# R7KA8P1AD register map
Vendor: Renesas Electronics Corporation; Series: RA8; File version: 1.10.02
CPU: CM85 r0p2, little endian, MPU, FPU, VTOR, 4 interrupt priority bits, 96 interrupts
Registers are 32-bit, read-write, reset 0x0 unless marked. A register's access mark holds for its fields unless they carry their own. Offsets are from the block's base; [hi:lo] are bit positions; {n}, {i} and the like mark numbered series; 'fields as' and 'values as' point back to an identical list.

## RMPU — Renesas Memory Protection Unit
Base 0x40000000
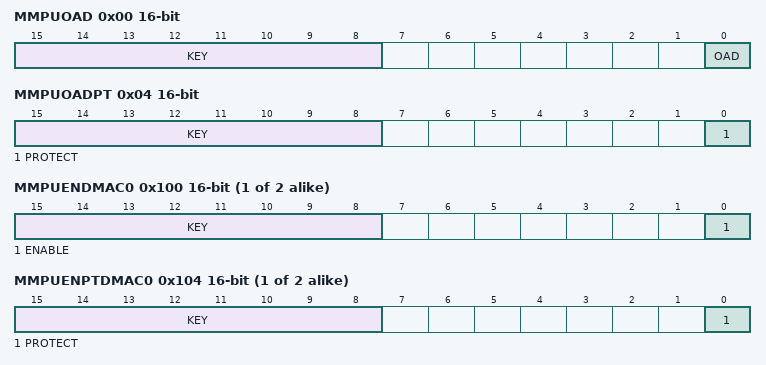
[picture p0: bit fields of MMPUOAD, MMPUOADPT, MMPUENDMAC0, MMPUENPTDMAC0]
0x00 MMPUOAD 16-bit — MMPU Operation After Detection Register
  [15:8] KEY — Key Code
  [0] OAD — Operation after detection
    0=IRQ; 1=Reset
0x04 MMPUOADPT 16-bit — MMPU Operation After Detection Protect Register
  [15:8] KEY wo — Key Code
  [0] PROTECT — Protection of register
    0=MMPUOAD register writing is possible; 1=MMPUOAD register writing is protected. Read is possible.
{0x100+0x200*i} MMPUENDMAC{i} (i=0..1) 16-bit — MMPU Enable Register for DMAC
  [15:8] KEY wo — Key Code
  [0] ENABLE — Bus master MPU of DMAC Enable
    0=Bus master MPU of DMAC is disabled; 1=Bus master MPU of DMAC is enabled
{0x104+0x200*i} MMPUENPTDMAC{i} (i=0..1) 16-bit — MMPU Enable Protect Register for DMAC {i}
  [15:8] KEY wo — Key Code
  [0] PROTECT — Protection of register
    0=MMPUENDMACm register write is possible; 1=MMPUENDMACm register write is protected. Read is possible.
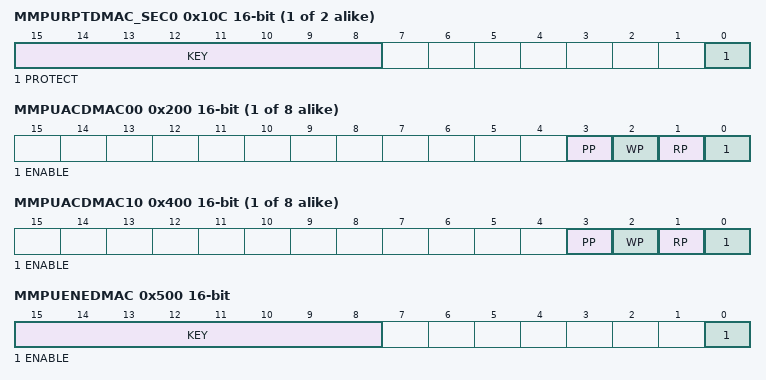
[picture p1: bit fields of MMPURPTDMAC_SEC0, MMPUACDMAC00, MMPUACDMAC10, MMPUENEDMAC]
{0x10C+0x200*i} MMPURPTDMAC_SEC{i} (i=0..1) 16-bit — MMPU Regions Protect Register for DMAC Secure {i}
  [15:8] KEY wo — Key Code
  [0] PROTECT — Protection of register
    0=Bus master MPU register for DMAC Secure write is possible; 1=Bus master MPU register for DMAC Secure write is protected. Read is possible.
{0x200+0x10*i} MMPUACDMAC0{i} (i=0..7) 16-bit — MMPU Access Control Register for DMAC
  [3] PP — Privilege protection
    0=Unprivileged access permission; 1=Unprivileged access protection
  [2] WP — Write protection
    0=Write permission; 1=Write protection
  [1] RP — Read protection
    0=Read permission; 1=Read protection
  [0] ENABLE — Region Enable
    0=DMAC region n unit is disabled; 1=DMAC region n unit is enabled
{0x204+0x10*i} MMPUSDMAC0{i} (i=0..7) (reset mask 0x1F) — MMPU Start Address Register for DMAC (n = 00 to 07)
{0x208+0x10*i} MMPUEDMAC0{i} (i=0..7) reset 0x1F (reset mask 0x1F) — MMPU End Address Register for DMAC (n = 00 to 07)
{0x400+0x10*i} MMPUACDMAC1{i} (i=0..7) 16-bit — MMPU Access Control Register for DMAC
  fields as MMPUACDMAC00
{0x404+0x10*i} MMPUSDMAC1{i} (i=0..7) (reset mask 0x1F) — MMPU Start Address Register for DMAC (n = 00 to 07)
{0x408+0x10*i} MMPUEDMAC1{i} (i=0..7) reset 0x1F (reset mask 0x1F) — MMPU End Address Register for DMAC (n = 00 to 07)
0x500 MMPUENEDMAC 16-bit — MMPU Enable Register for EDMAC
  [15:8] KEY wo — Key Code
  [0] ENABLE — Bus master MPU of EDMAC Enable
    0=Bus master MPU of EDMAC is disabled; 1=Bus master MPU of EDMAC is enabled
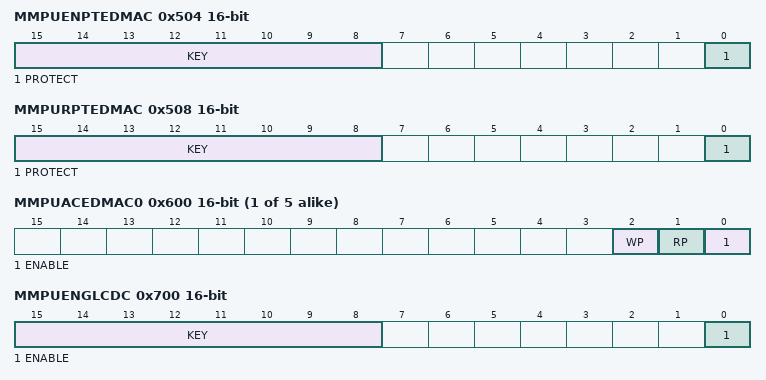
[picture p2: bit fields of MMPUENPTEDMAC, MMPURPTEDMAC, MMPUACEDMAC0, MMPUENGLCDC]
0x504 MMPUENPTEDMAC 16-bit — MMPU Enable Protect Register for EDMAC
  [15:8] KEY wo — Key Code
  [0] PROTECT — Protection of register
    0=MMPUENEDMAC register write is possible; 1=MMPUENEDMAC register write is protected. Read is possible.
0x508 MMPURPTEDMAC 16-bit — MMPU Regions Protect Register for EDMAC
  [15:8] KEY wo — Key Code
  [0] PROTECT — Protection of register
    0=Bus master MPU register for EDMAC write is possible; 1=Bus master MPU register for EDMAC write is protected. Read is possible.
{0x600+0x10*i} MMPUACEDMAC{i} (i=0..4) 16-bit — MMPU Access Control Register for EDMAC
  [2] WP — Write protection
    0=Write permission; 1=Write protection
  [1] RP — Read protection
    0=Read permission; 1=Read protection
  [0] ENABLE — Region Enable
    0=EDMAC region n unit is disabled; 1=EDMAC region n unit is enabled
{0x604+0x10*i} MMPUSEDMAC{i} (i=0..4) (reset mask 0x1F) — MMPU Start Address Register for EDMAC (n = 0 to 4)
{0x608+0x10*i} MMPUEEDMAC{i} (i=0..4) reset 0x1F (reset mask 0x1F) — MMPU End Address Register for EDMAC
0x700 MMPUENGLCDC 16-bit — MMPU Enable Register for GLCDC
  [15:8] KEY wo — Key Code
  [0] ENABLE — Bus master MPU of GLCDC Enable
    0=Bus master MPU of GLCDC is disabled; 1=Bus master MPU of GLCDC is enabled
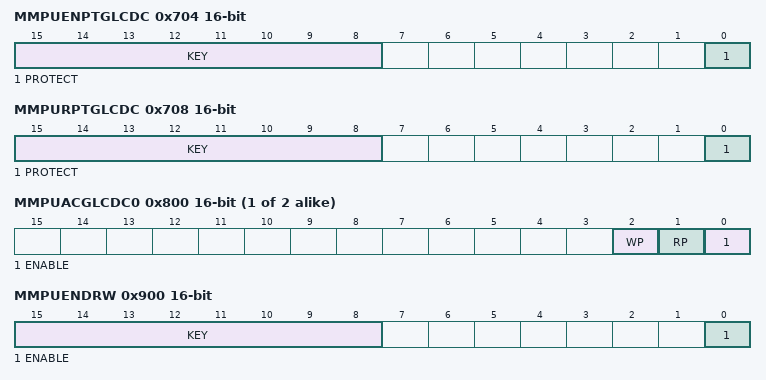
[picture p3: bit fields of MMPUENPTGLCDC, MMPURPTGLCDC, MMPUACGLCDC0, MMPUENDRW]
0x704 MMPUENPTGLCDC 16-bit — MMPU Enable Protect Register for GLCDC
  [15:8] KEY wo — Key Code
  [0] PROTECT — Protection of register
    0=MMPUENGLCDC register write is possible; 1=MMPUENGLCDC register write is protected. Read is possible.
0x708 MMPURPTGLCDC 16-bit — MMPU Regions Protect Register for GLCDC
  [15:8] KEY wo — Key Code
  [0] PROTECT — Protection of register
    0=Bus master MPU register for GLCDC write is possible; 1=Bus master MPU register for GLCDC write is protected. Read is possible.
{0x800+0x10*i} MMPUACGLCDC{i} (i=0..1) 16-bit — MMPU Access Control Register for GLCDC (n = 0, 1)
  [2] WP — Write protection
    0=Write permission; 1=Write protection
  [1] RP — Read protection
    0=Read permission; 1=Read protection
  [0] ENABLE — Region Enable
    0=GLCDC region n unit is disabled; 1=GLCDC region n unit is enabled
{0x804+0x10*i} MMPUSGLCDC{i} (i=0..1) (reset mask 0x3FF) — MMPU Start Address Register for GLCDC (n = 0, 1)
{0x808+0x10*i} MMPUEGLCDC{i} (i=0..1) reset 0x3FF (reset mask 0x3FF) — MMPU End Address Register for GLCDC (n = 0, 1)
0x900 MMPUENDRW 16-bit — MMPU Enable Register for DRW
  [15:8] KEY wo — Key Code
  [0] ENABLE — Bus master MPU of DRW Enable
    0=Bus master MPU of DRW is disabled; 1=Bus master MPU of DRW is enabled
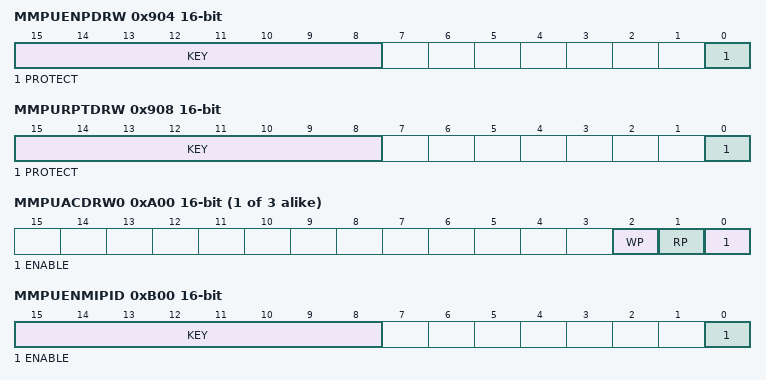
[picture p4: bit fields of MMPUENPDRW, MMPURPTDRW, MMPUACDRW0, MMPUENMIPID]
0x904 MMPUENPDRW 16-bit — MMPU Enable Protect Register for DRW
  [15:8] KEY wo — Key Code
  [0] PROTECT — Protection of register
    0=MMPUENDRW register write is possible; 1=MMPUENDRW register write is protected. Read is possible.
0x908 MMPURPTDRW 16-bit — MMPU Regions Protect Register for DRW
  [15:8] KEY wo — Key Code
  [0] PROTECT — Protection of register
    0=Bus master MPU register for DRW write is possible; 1=Bus master MPU register for DRW write is protected. Read is possible.
{0xA00+0x10*i} MMPUACDRW{i} (i=0..2) 16-bit — MMPU Access Control Register for DRW (n = 0 to 2)
  [2] WP — Write protection
    0=Write permission; 1=Write protection
  [1] RP — Read protection
    0=Read permission; 1=Read protection
  [0] ENABLE — Region Enable
    0=DRW region n unit is disabled; 1=DRW region n unit is enabled
{0xA04+0x10*i} MMPUSDRW{i} (i=0..2) (reset mask 0x3FF) — MMPU Start Address Register for DRW (n = 0 to 2)
{0xA08+0x10*i} MMPUEDRW{i} (i=0..2) reset 0x3FF (reset mask 0x3FF) — MMPU End Address Register for DRW (n = 0 to 2)
0xB00 MMPUENMIPID 16-bit — MMPU Enable Register for MIPI-DSI
  [15:8] KEY wo — Key Code
  [0] ENABLE — Bus master MPU of MIPI-DSI Enable
    0=Bus master MPU of MIPI-DSI is disabled; 1=Bus master MPU of MIPI-DSI is enabled
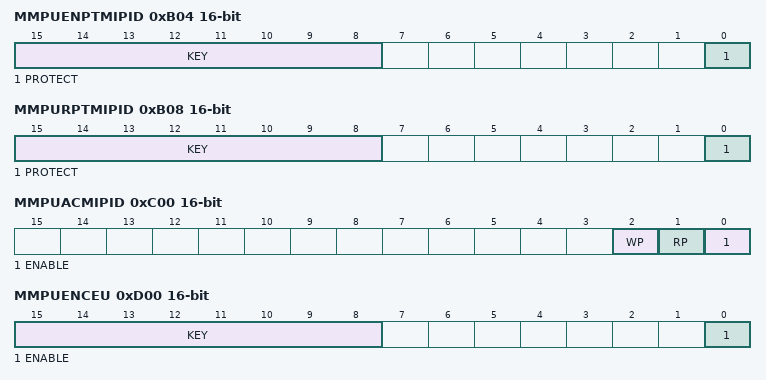
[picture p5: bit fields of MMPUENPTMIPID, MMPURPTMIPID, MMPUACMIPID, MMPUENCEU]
0xB04 MMPUENPTMIPID 16-bit — MMPU Enable Protect Register for MIPI-DSI
  [15:8] KEY wo — Key Code
  [0] PROTECT — Protection of register
    0=MMPUENMIPID register write is possible; 1=MMPUENMIPID register write is protected. Read is possible.
0xB08 MMPURPTMIPID 16-bit — MMPU Regions Protect Register for MIPI-DSI
  [15:8] KEY wo — Key Code
  [0] PROTECT — Protection of register
    0=Bus master MPU register for MIPI-DSI write is possible; 1=Bus master MPU register for MIPI-DSI write is protected. Read is possible.
0xC00 MMPUACMIPID 16-bit — MMPU Access Control Register for MIPI-DSI
  [2] WP — Write protection
    0=Write permission; 1=Write protection
  [1] RP — Read protection
    0=Read permission; 1=Read protection
  [0] ENABLE — Region Enable
    0=MIPI DSI region unit is disabled; 1=MIPI DSI region unit is enabled
0xC04 MMPUSMIPID (reset mask 0xFFF) — MMPU Start Address Register for MIPI-DSI
0xC08 MMPUEMIPID reset 0xFFF (reset mask 0xFFF) — MMPU End Address Register for MIPI-DSI
0xD00 MMPUENCEU 16-bit — MMPU Enable Register for CEU
  [15:8] KEY wo — Key Code
  [0] ENABLE — Bus master MPU of CEU Enable
    0=Bus master MPU of CEU is disabled; 1=Bus master MPU of CEU is enabled
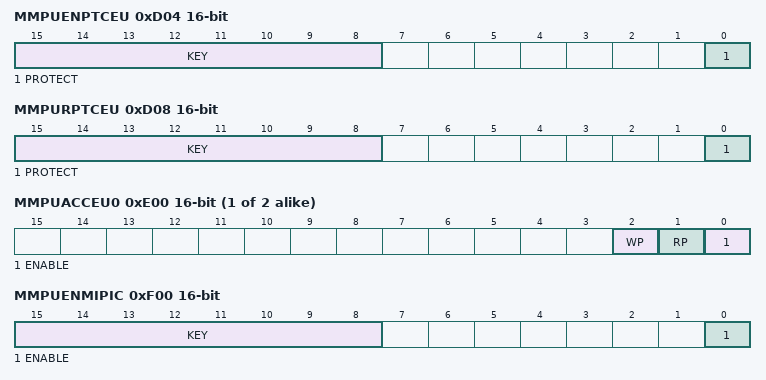
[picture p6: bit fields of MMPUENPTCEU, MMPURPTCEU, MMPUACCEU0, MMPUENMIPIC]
0xD04 MMPUENPTCEU 16-bit — MMPU Enable Protect Register for CEU
  [15:8] KEY wo — Key Code
  [0] PROTECT — Protection of register
    0=MMPUENCEU register write is possible; 1=MMPUENCEU register write is protected. Read is possible.
0xD08 MMPURPTCEU 16-bit — MMPU Regions Protect Register for CEU
  [15:8] KEY wo — Key Code
  [0] PROTECT — Protection of register
    0=Bus master MPU register for CEU write is possible; 1=Bus master MPU register for CEU write is protected. Read is possible.
{0xE00+0x10*i} MMPUACCEU{i} (i=0..1) 16-bit — MMPU Access Control Register for CEU (n = 0, 1)
  [2] WP — Write protection
    0=Write permission; 1=Write protection
  [1] RP — Read protection
    0=Read permission; 1=Read protection
  [0] ENABLE — Region Enable
    0=CEU region n unit is disabled; 1=CEU region n unit is enabled
{0xE04+0x10*i} MMPUSCEU{i} (i=0..1) (reset mask 0xFFF) — MMPU Start Address Register for CEU (n = 0, 1)
{0xE08+0x10*i} MMPUECEU{i} (i=0..1) reset 0xFFF (reset mask 0xFFF) — MMPU End Address Register for CEU (n = 0, 1)
0xF00 MMPUENMIPIC 16-bit — MMPU Enable Register for MIPI-CSI by VIN
  [15:8] KEY wo — Key Code
  [0] ENABLE — Bus master MPU of MIPI-CSI Enable
    0=Bus master MPU of MIPI-CSI is disabled; 1=Bus master MPU of MIPI-CSI is enabled
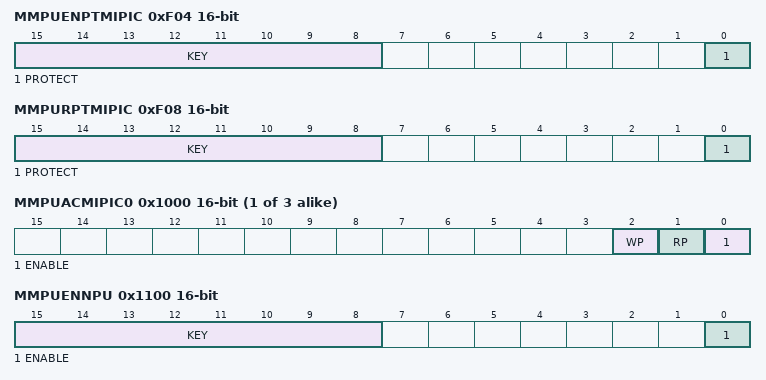
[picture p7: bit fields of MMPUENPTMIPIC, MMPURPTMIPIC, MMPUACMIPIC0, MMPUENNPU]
0xF04 MMPUENPTMIPIC 16-bit — MMPU Enable Protect Register for MIPI-CSI by VIN
  [15:8] KEY wo — Key Code
  [0] PROTECT — Protection of register
    0=MMPUENMIPIC register write is possible; 1=MMPUENMIPIC register write is protected. Read is possible.
0xF08 MMPURPTMIPIC 16-bit — MMPU Regions Protect Register for MIPI-CSI by VIN
  [15:8] KEY wo — Key Code
  [0] PROTECT — Protection of register
    0=Bus master MPU register for MIPI-CSI write is possible; 1=Bus master MPU register for MIPI-CSI write is protected. Read is possible.
{0x1000+0x10*i} MMPUACMIPIC{i} (i=0..2) 16-bit — MMPU Access Control Register for MIPI-CSI via VIN (n = 0 to 2)
  [2] WP — Write protection
    0=Write permission; 1=Write protection
  [1] RP — Read protection
    0=Read permission; 1=Read protection
  [0] ENABLE — Region Enable
    0=MIPI region n unit is disabled; 1=MIPI region n unit is enabled
{0x1004+0x10*i} MMPUSMIPIC{i} (i=0..2) (reset mask 0xFFF) — MMPU Start Address Register for MIPI-CSI via VIN (n = 0 to 2)
{0x1008+0x10*i} MMPUEMIPIC{i} (i=0..2) (reset mask 0xFFF) — MMPU End Address Register for MIPI-CSI via VIN (n = 0 to 2)
0x1100 MMPUENNPU 16-bit — MMPU Enable Register for NPU
  [15:8] KEY wo — Key Code
  [0] ENABLE — Bus master MPU of NPU Enable
    0=Bus master MPU of NPU is disabled; 1=Bus master MPU of NPU is enabled
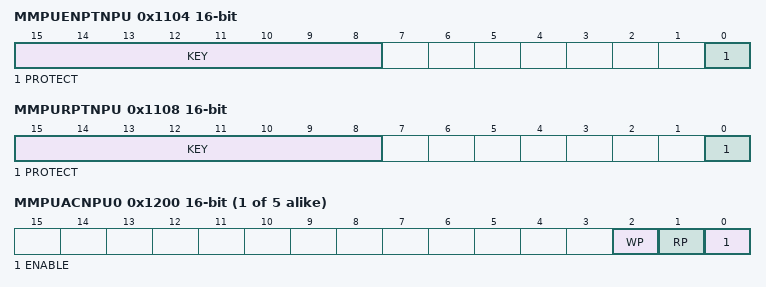
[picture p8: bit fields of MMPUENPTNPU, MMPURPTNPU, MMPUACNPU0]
0x1104 MMPUENPTNPU 16-bit — MMPU Enable Protect Register for NPU
  [15:8] KEY wo — Key Code
  [0] PROTECT — Protection of register
    0=MMPUENNPU register write is possible; 1=MMPUENNPU register write is protected. Read is possible.
0x1108 MMPURPTNPU 16-bit — MMPU Regions Protect Register for NPU
  [15:8] KEY wo — Key Code
  [0] PROTECT — Protection of register
    0=Bus master MPU register for NPU write is possible; 1=Bus master MPU register for NPU write is protected. Read is possible.
{0x1200+0x10*i} MMPUACNPU{i} (i=0..4) 16-bit — MMPU Access Control Register for NPU (n = 0 to 4)
  [2] WP — Write protection
    0=Write permission; 1=Write protection
  [1] RP — Read protection
    0=Read permission; 1=Read protection
  [0] ENABLE — Region Enable
    0=NPU region n unit is disabled; 1=NPU region n unit is enabled
{0x1204+0x10*i} MMPUSNPU{i} (i=0..4) (reset mask 0xFFF) — MMPU Start Address Register for NPU (n = 0 to 4)
{0x1208+0x10*i} MMPUENPU{i} (i=0..4) (reset mask 0xFFF) — MMPU End Address Register for NPU (n = 0 to 4)

## RMPU_NS — Renesas Memory Protection Unit
Base 0x50000000
Registers as RMPU, without MMPURPTDMAC_SEC*; these are added or differ:
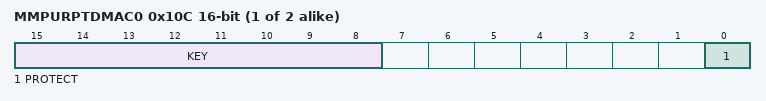
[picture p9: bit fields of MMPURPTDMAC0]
{0x10C+0x200*i} MMPURPTDMAC{i} (i=0..1) 16-bit — MMPU Regions Protect Register for DMAC Non-secure {i}
  [15:8] KEY wo — Key Code
  [0] PROTECT — Protection of register
    0=Bus master MPU register for DMAC write is possible; 1=Bus master MPU register for DMAC write is protected. Read is possible.

## Notices in the file
This software is supplied by Renesas Electronics Corporation and is only intended for
use with Renesas products. No other uses are authorized. This software is owned by
Renesas Electronics Corporation and is protected under all applicable laws, including
copyright laws.
THIS SOFTWARE IS PROVIDED "AS IS" AND RENESAS MAKES NO WARRANTIES REGARDING
THIS SOFTWARE, WHETHER EXPRESS, IMPLIED OR STATUTORY, INCLUDING BUT NOT LIMITED TO
WARRANTIES OF MERCHANTABILITY, FITNESS FOR A PARTICULAR PURPOSE AND NON-INFRINGEMENT.
ALL SUCH WARRANTIES ARE EXPRESSLY DISCLAIMED. TO THE MAXIMUM EXTENT PERMITTED NOT
PROHIBITED BY LAW, NEITHER RENESAS ELECTRONICS CORPORATION NOR ANY OF ITS AFFILIATED
COMPANIES SHALL BE LIABLE FOR ANY DIRECT, INDIRECT, SPECIAL, INCIDENTAL OR CONSEQUENTIAL
DAMAGES FOR ANY REASON RELATED TO THIS SOFTWARE, EVEN IF RENESAS OR ITS AFFILIATES HAVE
BEEN ADVISED OF THE POSSIBILITY OF SUCH DAMAGES.
Renesas reserves the right, without notice, to make changes to this software and to
discontinue the availability of this software. By using this software, you agree to
the additional terms and conditions found by accessing the following link:
http://www.renesas.com/disclaimer
